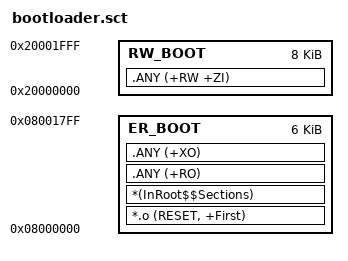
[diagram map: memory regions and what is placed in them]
LR_BOOT 0x08000000 0x00001800 {
  ER_BOOT 0x08000000 0x00001800 {
    *.o (RESET, +First)
    *(InRoot$$Sections)
    .ANY (+RO)
    .ANY (+XO)
  }
  RW_BOOT 0x20000000 0x00002000 {
    .ANY (+RW +ZI)
  }
}
